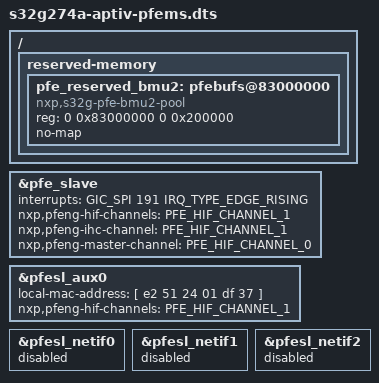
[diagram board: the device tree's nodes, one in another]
// SPDX-License-Identifier: GPL-2.0-or-later
/*
 * Copyright (C) 2023 Wind River Systems, Inc.
 *
 * This program is free software; you can redistribute it and/or modify
 * it under the terms of the GNU General Public License as published by
 * the Free Software Foundation; either version 2 of the License, or
 * (at your option) any later version.
 *
 * Based on s32g274a-rdb2-pfems.dts
 */

/dts-v1/;
#include "s32g274a-aptiv.dtsi"
#include "s32g-pfe-slave.dtsi"


/delete-node/ &pfe_reserved_bmu2;
/ {
	reserved-memory {
		pfe_reserved_bmu2: pfebufs@83000000 {
			compatible = "nxp,s32g-pfe-bmu2-pool";
			/* BMU2: 2 MB */
			reg = <0 0x83000000 0 0x200000>;
			no-map;
			status = "okay";
		};
	};
};

&pfe_slave {
	status = "okay";
	/delete-property/ dma-coherent; /* Disable for cut 1.1 compatibility OBE */
	interrupts = <GIC_SPI 191 IRQ_TYPE_EDGE_RISING>;
	interrupt-names = "hif1";
	nxp,pfeng-hif-channels = <PFE_HIF_CHANNEL_1>;
	nxp,pfeng-ihc-channel = <PFE_HIF_CHANNEL_1>;
	nxp,pfeng-master-channel = <PFE_HIF_CHANNEL_0>;
};

&pfesl_aux0 {
	status = "okay";
	local-mac-address = [ e2 51 24 01 df 37 ];
	nxp,pfeng-hif-channels = <PFE_HIF_CHANNEL_1>;
};

&pfesl_netif0 {
	status = "disabled";
};

&pfesl_netif1 {
	status = "disabled";
};

&pfesl_netif2 {
	status = "disabled";
};
